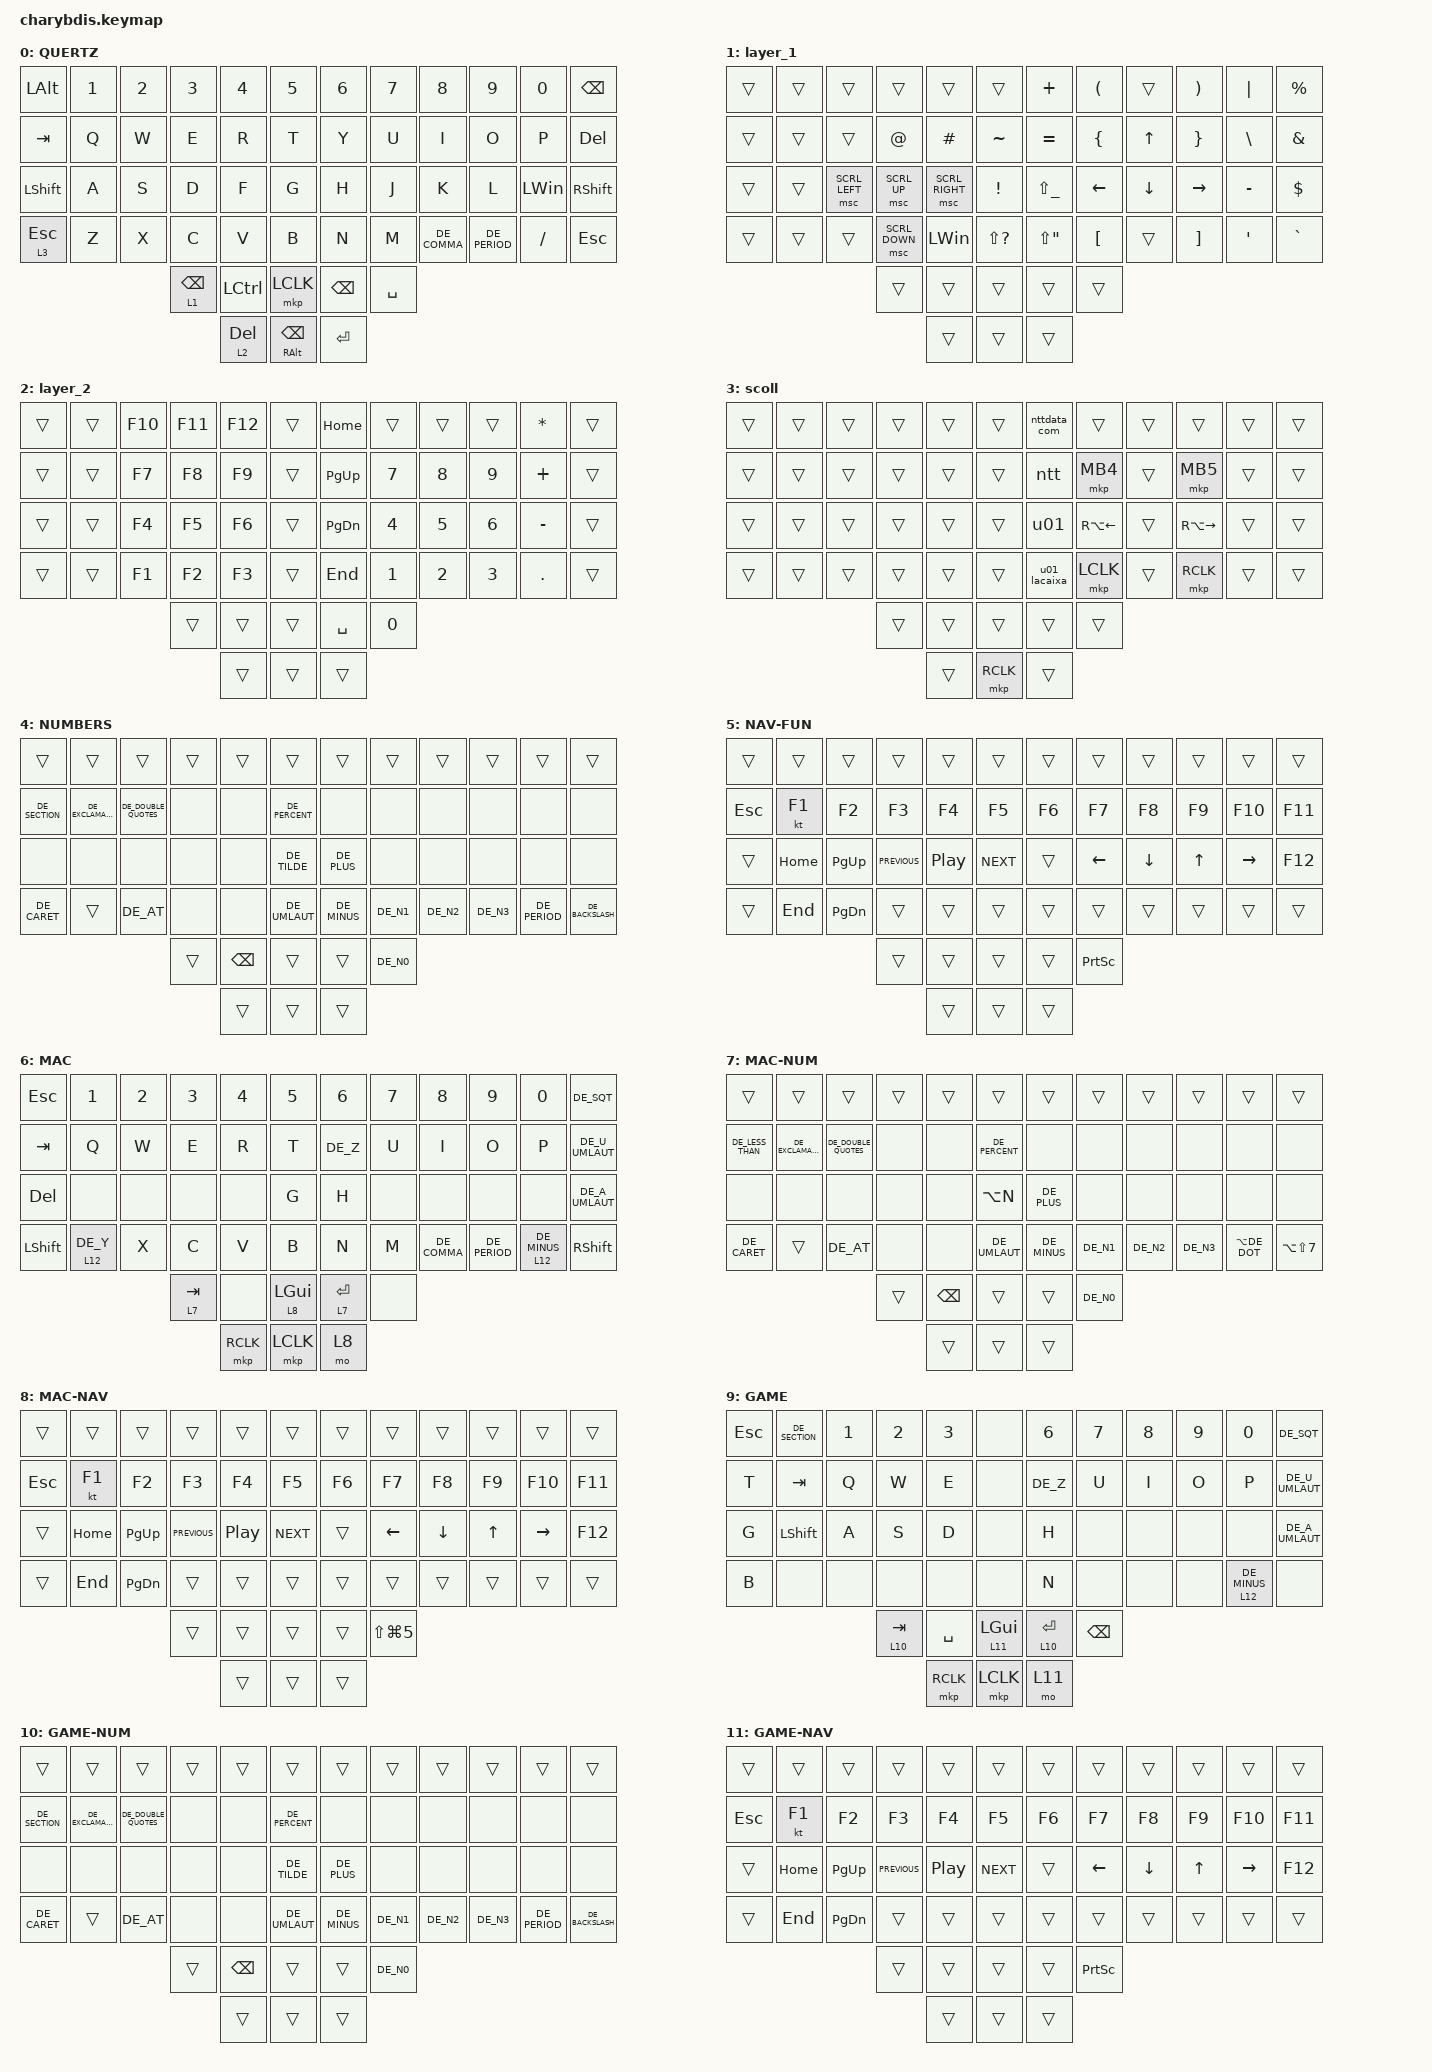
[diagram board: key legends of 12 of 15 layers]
#include "keys_de_swiss.h"
#include <dt-bindings/zmk/mouse.h>
#include <behaviors/mouse_keys.dtsi>
#include <behaviors.dtsi>
#include <dt-bindings/zmk/bt.h>
#include <dt-bindings/zmk/ext_power.h>
#include <dt-bindings/zmk/keys.h>
#include <dt-bindings/zmk/pointing.h>

// / {
//     chosen { zmk,matrix_transform = &default_transform; };
// };

/ {
    /* input config for mouse move mode */

    trackball_listener {
        compatible = "zmk,input-behavior-listener";
        device = <&vtrackball>;
        layers = <0 1 2 3>;
        evt-type = <INPUT_EV_REL>;
        x-input-code = <INPUT_REL_X>;
        y-input-code = <INPUT_REL_Y>;
        scale-multiplier = <1>;
        scale-divisor = <2>;

        // bindings = <&ib_toggle_layer 7>;
    };

    /* input config for snipe mode */

    trackball_snipe_listener {
        compatible = "zmk,input-behavior-listener";
        device = <&vtrackball>;
        layers = <10>;
        evt-type = <INPUT_EV_REL>;
        x-input-code = <INPUT_REL_X>;
        y-input-code = <INPUT_REL_Y>;
        scale-multiplier = <1>;
        scale-divisor = <4>;
    };

    /* input config for mouse scroll mode */

    trackball_scroll_listener {
        compatible = "zmk,input-behavior-listener";
        device = <&vtrackball>;
        layers = <3>;
        evt-type = <INPUT_EV_REL>;
        x-input-code = <INPUT_REL_MISC>;
        y-input-code = <INPUT_REL_WHEEL>;
        y-invert;
        bindings = <&ib_wheel_scaler 1 14>;
    };

    /* define a resolution down scaler only for INPUT_REL_WHEEL */

    ib_wheel_scaler: ib_wheel_scaler {
        compatible = "zmk,input-behavior-scaler";
        #binding-cells = <2>;
        evt-type = <INPUT_EV_REL>;
        input-code = <INPUT_REL_WHEEL>;
    };

    /* adjust cooldown waiting period for mouse key layer after activated */

    ib_toggle_layer: ib_toggle_layer {
        compatible = "zmk,input-behavior-tog-layer";
        #binding-cells = <1>;
        time-to-live-ms = <750>;
    };

    // #define QUERTZ    0
    // #define NUMBERS   1
    // #define NAV-FUN   2
    // #define MAC       3
    // #define MAC-NUM   4
    // #define MAC-NAV   5
    // #define GAME      6
    // #define GAME-NUM  7
    // #define GAME-NAV  8
    // #define SCROLL    9
    // #define SNIPER   10
    // #define FN       11

    combos { compatible = "zmk,combos"; };

    macros {
        ntt: ntt {
            compatible = "zmk,behavior-macro";
            #binding-cells = <0>;
            bindings = <&kp L &kp B &kp E &kp L &kp L &kp S &kp O &kp S &kp AT &kp E &kp M &kp E &kp A &kp L &kp DOT &kp N &kp T &kp T &kp D &kp A &kp T &kp A &kp DOT &kp C &kp O &kp M>;
            label = "NTT";
        };

        nttdata_com: nttdata_com {
            compatible = "zmk,behavior-macro";
            #binding-cells = <0>;
            bindings = <&kp L &kp U &kp I &kp S &kp M &kp O &kp I &kp S &kp E &kp S &kp DOT &kp B &kp E &kp L &kp L &kp O &kp S &kp O &kp S &kp A &kp AT &kp E &kp M &kp E &kp A &kp L &kp DOT &kp N &kp T &kp T &kp D &kp A &kp T &kp A &kp DOT &kp C &kp O &kp M>;
            label = "NTTDATA_COM";
        };

        u01_lacaixa: u01_lacaixa {
            compatible = "zmk,behavior-macro";
            #binding-cells = <0>;
            bindings = <&kp U &kp N0 &kp N1 &kp A &kp N7 &kp B &kp N6 &kp D &kp AT &kp L &kp A &kp C &kp A &kp I &kp X &kp A &kp DOT &kp E &kp S>;
            label = "U01_LACAIXA";
        };

        u01: u01 {
            compatible = "zmk,behavior-macro";
            #binding-cells = <0>;
            bindings = <&kp U &kp N0 &kp N1 &kp A &kp N7 &kp B &kp N6 &kp D>;
            label = "U01";
        };
    };

    keymap {
        compatible = "zmk,keymap";

        default_win_layer {
            bindings = <
&kp LALT        &kp N1  &kp N2  &kp N3           &kp N4            &kp N5                     &kp N6         &kp N7     &kp N8        &kp N9         &kp N0        &kp BACKSPACE
&kp TAB         &kp Q   &kp W   &kp E            &kp R             &kp T                      &kp Y          &kp U      &kp I         &kp O          &kp P         &kp DELETE
&kp LEFT_SHIFT  &kp A   &kp S   &kp D            &kp F             &kp G                      &kp H          &kp J      &kp K         &kp L          &kp LEFT_WIN  &kp RIGHT_SHIFT
&lt 3 ESC       &kp Z   &kp X   &kp C            &kp V             &kp B                      &kp N          &kp M      &kp DE_COMMA  &kp DE_PERIOD  &kp FSLH      &kp ESCAPE
                                &lt 1 BACKSPACE  &kp LEFT_CONTROL  &mkp LCLK                  &kp BACKSPACE  &kp SPACE
                                                 &lt 2 DELETE      &mt RIGHT_ALT BACKSPACE    &kp ENTER
            >;

            label = "QUERTZ";
        };

        layer_1 {
            bindings = <
&trans  &trans  &trans          &trans          &trans           &trans           &kp PLUS       &kp LPAR        &trans    &kp RPAR         &kp PIPE   &kp PRCNT
&trans  &trans  &trans          &kp AT          &kp POUND        &kp TILDE        &kp EQUAL      &kp LBRC        &kp UP    &kp RBRC         &kp BSLH   &kp AMPS
&trans  &trans  &msc SCRL_LEFT  &msc SCRL_UP    &msc SCRL_RIGHT  &kp EXCL         &kp LS(UNDER)  &kp LEFT_ARROW  &kp DOWN  &kp RIGHT_ARROW  &kp MINUS  &kp DLLR
&trans  &trans  &trans          &msc SCRL_DOWN  &kp LEFT_WIN     &kp LS(QMARK)    &kp LS(DQT)    &kp LBKT        &trans    &kp RBKT         &kp SQT    &kp GRAVE
                                &trans          &trans           &trans           &trans         &trans
                                                &trans           &trans           &trans
            >;
        };

        layer_2 {
            bindings = <
&trans  &trans  &kp F10  &kp F11  &kp F12  &trans    &kp HOME   &trans  &trans  &trans  &kp STAR   &trans
&trans  &trans  &kp F7   &kp F8   &kp F9   &trans    &kp PG_UP  &kp N7  &kp N8  &kp N9  &kp PLUS   &trans
&trans  &trans  &kp F4   &kp F5   &kp F6   &trans    &kp PG_DN  &kp N4  &kp N5  &kp N6  &kp MINUS  &trans
&trans  &trans  &kp F1   &kp F2   &kp F3   &trans    &kp END    &kp N1  &kp N2  &kp N3  &kp DOT    &trans
                         &trans   &trans   &trans    &kp SPACE  &kp N0
                                  &trans   &trans    &trans
            >;
        };

        scroll {
            bindings = <
&trans  &trans  &trans  &trans  &trans  &trans       &nttdata_com  &trans              &trans  &trans               &trans  &trans
&trans  &trans  &trans  &trans  &trans  &trans       &ntt          &mkp MB4            &trans  &mkp MB5             &trans  &trans
&trans  &trans  &trans  &trans  &trans  &trans       &u01          &kp RA(LEFT_ARROW)  &trans  &kp RA(RIGHT_ARROW)  &trans  &trans
&trans  &trans  &trans  &trans  &trans  &trans       &u01_lacaixa  &mkp LCLK           &trans  &mkp RCLK            &trans  &trans
                        &trans  &trans  &trans       &trans        &trans
                                &trans  &mkp RCLK    &trans
            >;

            label = "scoll";
        };

        win_raise_layer {
            bindings = <
&trans          &trans              &trans                &trans  &trans         &trans            &trans        &trans     &trans     &trans     &trans         &trans
&kp DE_SECTION  &kp DE_EXCLAMATION  &kp DE_DOUBLE_QUOTES  &none   &none          &kp DE_PERCENT    &none         &none      &none      &none      &none          &none
&none           &none               &none                 &none   &none          &kp DE_TILDE      &kp DE_PLUS   &none      &none      &none      &none          &none
&kp DE_CARET    &trans              &kp DE_AT             &none   &none          &kp DE_UMLAUT     &kp DE_MINUS  &kp DE_N1  &kp DE_N2  &kp DE_N3  &kp DE_PERIOD  &kp DE_BACKSLASH
                                                          &trans  &kp BACKSPACE  &trans            &trans        &kp DE_N0
                                                                  &trans         &trans            &trans
            >;

            label = "NUMBERS";
        };

        win_lower_layer {
            bindings = <
&trans      &trans    &trans         &trans          &trans            &trans        &trans  &trans           &trans          &trans        &trans           &trans
&kp ESCAPE  &kt F1    &kp F2         &kp F3          &kp F4            &kp F5        &kp F6  &kp F7           &kp F8          &kp F9        &kp F10          &kp F11
&trans      &kp HOME  &kp PAGE_UP    &kp C_PREVIOUS  &kp C_PLAY_PAUSE  &kp C_NEXT    &trans  &kp LEFT_ARROW   &kp DOWN_ARROW  &kp UP_ARROW  &kp RIGHT_ARROW  &kp F12
&trans      &kp END   &kp PAGE_DOWN  &trans          &trans            &trans        &trans  &trans           &trans          &trans        &trans           &trans
                                     &trans          &trans            &trans        &trans  &kp PRINTSCREEN
                                                     &trans            &trans        &trans
            >;

            label = "NAV-FUN";
        };

        default_mac_layer {
            label = "MAC";
            bindings = <
&kp ESCAPE      &kp N1       &kp N2  &kp N3     &kp N4     &kp N5            &kp N6       &kp N7  &kp N8        &kp N9         &kp N0           &kp DE_SQT
&kp TAB         &kp Q        &kp W   &kp E      &kp R      &kp T             &kp DE_Z     &kp U   &kp I         &kp O          &kp P            &kp DE_U_UMLAUT
&kp DELETE      &none        &none   &none      &none      &kp G             &kp H        &none   &none         &none          &none            &kp DE_A_UMLAUT
&kp LEFT_SHIFT  &lt 12 DE_Y  &kp X   &kp C      &kp V      &kp B             &kp N        &kp M   &kp DE_COMMA  &kp DE_PERIOD  &lt 12 DE_MINUS  &kp RSHIFT
                                     &lt 7 TAB  &none      &lt 8 LEFT_GUI    &lt 7 ENTER  &none
                                                &mkp RCLK  &mkp LCLK         &mo 8
            >;
        };

        mac_raise_layer {
            label = "MAC-NUM";
            bindings = <
&trans            &trans              &trans                &trans  &trans         &trans            &trans        &trans     &trans     &trans     &trans          &trans
&kp DE_LESS_THAN  &kp DE_EXCLAMATION  &kp DE_DOUBLE_QUOTES  &none   &none          &kp DE_PERCENT    &none         &none      &none      &none      &none           &none
&none             &none               &none                 &none   &none          &kp LA(N)         &kp DE_PLUS   &none      &none      &none      &none           &none
&kp DE_CARET      &trans              &kp DE_AT             &none   &none          &kp DE_UMLAUT     &kp DE_MINUS  &kp DE_N1  &kp DE_N2  &kp DE_N3  &kp LA(DE_DOT)  &kp LA(LS(NUMBER_7))
                                                            &trans  &kp BACKSPACE  &trans            &trans        &kp DE_N0
                                                                    &trans         &trans            &trans
            >;
        };

        mac_lower_layer {
            label = "MAC-NAV";
            bindings = <
&trans      &trans    &trans         &trans          &trans            &trans        &trans  &trans                &trans          &trans        &trans           &trans
&kp ESCAPE  &kt F1    &kp F2         &kp F3          &kp F4            &kp F5        &kp F6  &kp F7                &kp F8          &kp F9        &kp F10          &kp F11
&trans      &kp HOME  &kp PAGE_UP    &kp C_PREVIOUS  &kp C_PLAY_PAUSE  &kp C_NEXT    &trans  &kp LEFT_ARROW        &kp DOWN_ARROW  &kp UP_ARROW  &kp RIGHT_ARROW  &kp F12
&trans      &kp END   &kp PAGE_DOWN  &trans          &trans            &trans        &trans  &trans                &trans          &trans        &trans           &trans
                                     &trans          &trans            &trans        &trans  &kp LS(LG(NUMBER_5))
                                                     &trans            &trans        &trans
            >;
        };

        default_game_layer {
            label = "GAME";
            bindings = <
&kp ESCAPE  &kp DE_SECTION  &kp N1  &kp N2      &kp N3     &none              &kp N6        &kp N7         &kp N8  &kp N9  &kp N0           &kp DE_SQT
&kp T       &kp TAB         &kp Q   &kp W       &kp E      &none              &kp DE_Z      &kp U          &kp I   &kp O   &kp P            &kp DE_U_UMLAUT
&kp G       &kp LEFT_SHIFT  &kp A   &kp S       &kp D      &none              &kp H         &none          &none   &none   &none            &kp DE_A_UMLAUT
&kp B       &none           &none   &none       &none      &none              &kp N         &none          &none   &none   &lt 12 DE_MINUS  &none
                                    &lt 10 TAB  &kp SPACE  &lt 11 LEFT_GUI    &lt 10 ENTER  &kp BACKSPACE
                                                &mkp RCLK  &mkp LCLK          &mo 11
            >;
        };

        game_raise_layer {
            label = "GAME-NUM";
            bindings = <
&trans          &trans              &trans                &trans  &trans         &trans            &trans        &trans     &trans     &trans     &trans         &trans
&kp DE_SECTION  &kp DE_EXCLAMATION  &kp DE_DOUBLE_QUOTES  &none   &none          &kp DE_PERCENT    &none         &none      &none      &none      &none          &none
&none           &none               &none                 &none   &none          &kp DE_TILDE      &kp DE_PLUS   &none      &none      &none      &none          &none
&kp DE_CARET    &trans              &kp DE_AT             &none   &none          &kp DE_UMLAUT     &kp DE_MINUS  &kp DE_N1  &kp DE_N2  &kp DE_N3  &kp DE_PERIOD  &kp DE_BACKSLASH
                                                          &trans  &kp BACKSPACE  &trans            &trans        &kp DE_N0
                                                                  &trans         &trans            &trans
            >;
        };

        game_lower_layer {
            label = "GAME-NAV";
            bindings = <
&trans      &trans    &trans         &trans          &trans            &trans        &trans  &trans           &trans          &trans        &trans           &trans
&kp ESCAPE  &kt F1    &kp F2         &kp F3          &kp F4            &kp F5        &kp F6  &kp F7           &kp F8          &kp F9        &kp F10          &kp F11
&trans      &kp HOME  &kp PAGE_UP    &kp C_PREVIOUS  &kp C_PLAY_PAUSE  &kp C_NEXT    &trans  &kp LEFT_ARROW   &kp DOWN_ARROW  &kp UP_ARROW  &kp RIGHT_ARROW  &kp F12
&trans      &kp END   &kp PAGE_DOWN  &trans          &trans            &trans        &trans  &trans           &trans          &trans        &trans           &trans
                                     &trans          &trans            &trans        &trans  &kp PRINTSCREEN
                                                     &trans            &trans        &trans
            >;
        };

        scroll_layer {
            bindings = <
&trans  &trans  &trans          &trans  &trans          &trans    &trans  &trans           &trans  &trans           &trans  &trans
&trans  &trans  &trans          &trans  &trans          &trans    &trans  &trans           &trans  &trans           &trans  &trans
&trans  &trans  &trans          &trans  &kp LEFT_SHIFT  &trans    &trans  &kp RIGHT_SHIFT  &trans  &trans           &trans  &trans
&trans  &trans  &kp LEFT_SHIFT  &trans  &trans          &trans    &trans  &trans           &trans  &kp RIGHT_SHIFT  &trans  &trans
                                &trans  &trans          &trans    &trans  &trans
                                        &trans          &trans    &trans
            >;

            label = "SCROLL";
        };

        sniper_layer {
            bindings = <
&trans  &trans  &trans  &trans  &trans  &trans    &trans  &trans  &trans  &trans  &trans  &trans
&trans  &trans  &trans  &trans  &trans  &trans    &trans  &trans  &trans  &trans  &trans  &trans
&trans  &trans  &trans  &trans  &trans  &trans    &trans  &trans  &trans  &trans  &trans  &trans
&trans  &trans  &trans  &trans  &trans  &trans    &trans  &trans  &trans  &trans  &trans  &trans
                        &trans  &trans  &trans    &trans  &trans
                                &trans  &trans    &trans
            >;

            label = "SNIPER";
        };

        keeb_pref_layer {
            label = "FN";
            bindings = <
&ext_power EP_TOG  &trans        &trans        &trans        &trans        &trans          &trans  &trans  &trans  &trans  &trans  &trans
&trans             &trans        &trans        &trans        &trans        &trans          &trans  &trans  &trans  &trans  &trans  &trans
&bt BT_CLR         &bt BT_SEL 0  &bt BT_SEL 1  &bt BT_SEL 2  &bt BT_SEL 3  &bt BT_SEL 4    &trans  &trans  &trans  &trans  &trans  &trans
&trans             &trans        &trans        &trans        &trans        &trans          &trans  &trans  &trans  &trans  &trans  &trans
                                               &trans        &trans        &trans          &trans  &trans
                                                             &trans        &trans          &trans
            >;
        };
    };
};
